# bcm2711_lpa register map
Vendor: BROADCOM; Series: BCM2711; File version: A
CPU: CA72 r0p0, little endian, 2 interrupt priority bits
Registers are 32-bit, read-write, reset 0x0 unless marked. A register's access mark holds for its fields unless they carry their own. Offsets are from the block's base; [hi:lo] are bit positions; {n}, {i} and the like mark numbered series.

## GPIO — Pin level and mux control
Base 0xFE200000
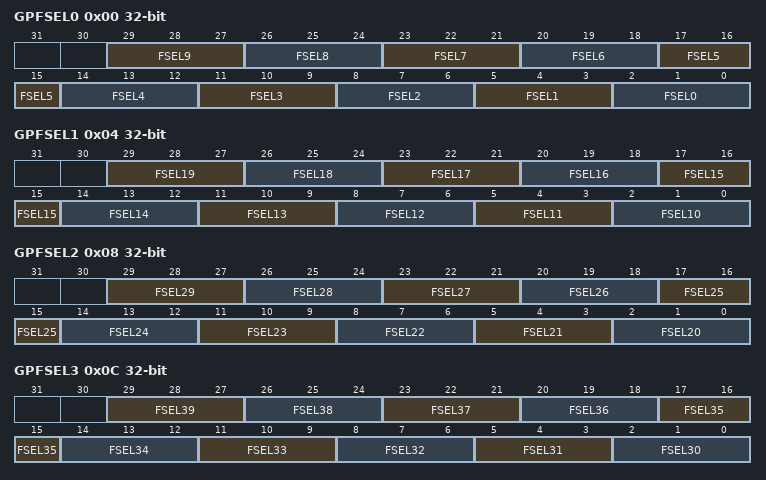
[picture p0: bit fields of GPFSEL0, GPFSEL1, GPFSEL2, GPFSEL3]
0x00 GPFSEL0 reset not defined — GPIO Function Select 0
  [29:27] FSEL9 — Function Select 9
    0=INPUT (Pin is an input); 1=OUTPUT (Pin is an output); 4=SPI0_MISO (Pin is connected to SPI0_MISO); 5=SD1 (Pin is connected to SD1); 6=DPI_D5 (Pin is connected to DPI_D5); 7=BSCSL_MISO (Pin is connected to BSCSL_MISO); 3=RXD4 (Pin is connected to RXD4); 2=SCL4 (Pin is connected to SCL4)
  [26:24] FSEL8 — Function Select 8
    0=INPUT (Pin is an input); 1=OUTPUT (Pin is an output); 4=SPI0_CE0_N (Pin is connected to SPI0_CE0_N); 5=SD0 (Pin is connected to SD0); 6=DPI_D4 (Pin is connected to DPI_D4); 7=BSCSL_CE_N (Pin is connected to BSCSL_CE_N); 3=TXD4 (Pin is connected to TXD4); 2=SDA4 (Pin is connected to SDA4)
  [23:21] FSEL7 — Function Select 7
    0=INPUT (Pin is an input); 1=OUTPUT (Pin is an output); 4=SPI0_CE1_N (Pin is connected to SPI0_CE1_N); 5=SWE_N (Pin is connected to SWE_N); 6=DPI_D3 (Pin is connected to DPI_D3); 7=SPI4_SCLK (Pin is connected to SPI4_SCLK); 3=RTS3 (Pin is connected to RTS3); 2=SCL4 (Pin is connected to SCL4)
  [20:18] FSEL6 — Function Select 6
    0=INPUT (Pin is an input); 1=OUTPUT (Pin is an output); 4=GPCLK2 (Pin is connected to GPCLK2); 5=SOE_N (Pin is connected to SOE_N); 6=DPI_D2 (Pin is connected to DPI_D2); 7=SPI4_MOSI (Pin is connected to SPI4_MOSI); 3=CTS3 (Pin is connected to CTS3); 2=SDA4 (Pin is connected to SDA4)
  [17:15] FSEL5 — Function Select 5
    0=INPUT (Pin is an input); 1=OUTPUT (Pin is an output); 4=GPCLK1 (Pin is connected to GPCLK1); 5=SA0 (Pin is connected to SA0); 6=DPI_D1 (Pin is connected to DPI_D1); 7=SPI4_MISO (Pin is connected to SPI4_MISO); 3=RXD3 (Pin is connected to RXD3); 2=SCL3 (Pin is connected to SCL3)
  [14:12] FSEL4 — Function Select 4
    0=INPUT (Pin is an input); 1=OUTPUT (Pin is an output); 4=GPCLK0 (Pin is connected to GPCLK0); 5=SA1 (Pin is connected to SA1); 6=DPI_D0 (Pin is connected to DPI_D0); 7=SPI4_CE0_N (Pin is connected to SPI4_CE0_N); 3=TXD3 (Pin is connected to TXD3); 2=SDA3 (Pin is connected to SDA3)
  [11:9] FSEL3 — Function Select 3
    0=INPUT (Pin is an input); 1=OUTPUT (Pin is an output); 4=SCL1 (Pin is connected to SCL1); 5=SA2 (Pin is connected to SA2); 6=LCD_HSYNC (Pin is connected to LCD_HSYNC); 7=SPI3_SCLK (Pin is connected to SPI3_SCLK); 3=RTS2 (Pin is connected to RTS2); 2=SCL3 (Pin is connected to SCL3)
  [8:6] FSEL2 — Function Select 2
    0=INPUT (Pin is an input); 1=OUTPUT (Pin is an output); 4=SDA1 (Pin is connected to SDA1); 5=SA3 (Pin is connected to SA3); 6=LCD_VSYNC (Pin is connected to LCD_VSYNC); 7=SPI3_MOSI (Pin is connected to SPI3_MOSI); 3=CTS2 (Pin is connected to CTS2); 2=SDA3 (Pin is connected to SDA3)
  [5:3] FSEL1 — Function Select 1
    0=INPUT (Pin is an input); 1=OUTPUT (Pin is an output); 4=SCL0 (Pin is connected to SCL0); 5=SA4 (Pin is connected to SA4); 6=DE (Pin is connected to DE); 7=SPI3_MISO (Pin is connected to SPI3_MISO); 3=RXD2 (Pin is connected to RXD2); 2=SCL6 (Pin is connected to SCL6)
  [2:0] FSEL0 — Function Select 0
    0=INPUT (Pin is an input); 1=OUTPUT (Pin is an output); 4=SDA0 (Pin is connected to SDA0); 5=SA5 (Pin is connected to SA5); 6=PCLK (Pin is connected to PCLK); 7=SPI3_CE0_N (Pin is connected to SPI3_CE0_N); 3=TXD2 (Pin is connected to TXD2); 2=SDA6 (Pin is connected to SDA6)
0x04 GPFSEL1 reset not defined — GPIO Function Select 1
  [29:27] FSEL19 — Function Select 19
    0=INPUT (Pin is an input); 1=OUTPUT (Pin is an output); 4=PCM_FS (Pin is connected to PCM_FS); 5=SD11 (Pin is connected to SD11); 6=DPI_D15 (Pin is connected to DPI_D15); 7=SPI6_MISO (Pin is connected to SPI6_MISO); 3=SPI1_MISO (Pin is connected to SPI1_MISO); 2=PWM0_1 (Pin is connected to PWM0_1)
  [26:24] FSEL18 — Function Select 18
    0=INPUT (Pin is an input); 1=OUTPUT (Pin is an output); 4=PCM_CLK (Pin is connected to PCM_CLK); 5=SD10 (Pin is connected to SD10); 6=DPI_D14 (Pin is connected to DPI_D14); 7=SPI6_CE0_N (Pin is connected to SPI6_CE0_N); 3=SPI1_CE0_N (Pin is connected to SPI1_CE0_N); 2=PWM0_0 (Pin is connected to PWM0_0)
  [23:21] FSEL17 — Function Select 17
    0=INPUT (Pin is an input); 1=OUTPUT (Pin is an output); 5=SD9 (Pin is connected to SD9); 6=DPI_D13 (Pin is connected to DPI_D13); 7=RTS0 (Pin is connected to RTS0); 3=SPI1_CE1_N (Pin is connected to SPI1_CE1_N); 2=RTS1 (Pin is connected to RTS1)
  [20:18] FSEL16 — Function Select 16
    0=INPUT (Pin is an input); 1=OUTPUT (Pin is an output); 5=SD8 (Pin is connected to SD8); 6=DPI_D12 (Pin is connected to DPI_D12); 7=CTS0 (Pin is connected to CTS0); 3=SPI1_CE2_N (Pin is connected to SPI1_CE2_N); 2=CTS1 (Pin is connected to CTS1)
  [17:15] FSEL15 — Function Select 15
    0=INPUT (Pin is an input); 1=OUTPUT (Pin is an output); 4=RXD0 (Pin is connected to RXD0); 5=SD7 (Pin is connected to SD7); 6=DPI_D11 (Pin is connected to DPI_D11); 7=SPI5_SCLK (Pin is connected to SPI5_SCLK); 3=RTS5 (Pin is connected to RTS5); 2=RXD1 (Pin is connected to RXD1)
  [14:12] FSEL14 — Function Select 14
    0=INPUT (Pin is an input); 1=OUTPUT (Pin is an output); 4=TXD0 (Pin is connected to TXD0); 5=SD6 (Pin is connected to SD6); 6=DPI_D10 (Pin is connected to DPI_D10); 7=SPI5_MOSI (Pin is connected to SPI5_MOSI); 3=CTS5 (Pin is connected to CTS5); 2=TXD1 (Pin is connected to TXD1)
  [11:9] FSEL13 — Function Select 13
    0=INPUT (Pin is an input); 1=OUTPUT (Pin is an output); 4=PWM0_1 (Pin is connected to PWM0_1); 5=SD5 (Pin is connected to SD5); 6=DPI_D9 (Pin is connected to DPI_D9); 7=SPI5_MISO (Pin is connected to SPI5_MISO); 3=RXD5 (Pin is connected to RXD5); 2=SCL5 (Pin is connected to SCL5)
  [8:6] FSEL12 — Function Select 12
    0=INPUT (Pin is an input); 1=OUTPUT (Pin is an output); 4=PWM0_0 (Pin is connected to PWM0_0); 5=SD4 (Pin is connected to SD4); 6=DPI_D8 (Pin is connected to DPI_D8); 7=SPI5_CE0_N (Pin is connected to SPI5_CE0_N); 3=TXD5 (Pin is connected to TXD5); 2=SDA5 (Pin is connected to SDA5)
  [5:3] FSEL11 — Function Select 11
    0=INPUT (Pin is an input); 1=OUTPUT (Pin is an output); 4=SPI0_SCLK (Pin is connected to SPI0_SCLK); 5=SD3 (Pin is connected to SD3); 6=DPI_D7 (Pin is connected to DPI_D7); 7=BSCSL_SCLK (Pin is connected to BSCSL_SCLK); 3=RTS4 (Pin is connected to RTS4); 2=SCL5 (Pin is connected to SCL5)
  [2:0] FSEL10 — Function Select 10
    0=INPUT (Pin is an input); 1=OUTPUT (Pin is an output); 4=SPI0_MOSI (Pin is connected to SPI0_MOSI); 5=SD2 (Pin is connected to SD2); 6=DPI_D6 (Pin is connected to DPI_D6); 7=BSCSL_MOSI (Pin is connected to BSCSL_MOSI); 3=CTS4 (Pin is connected to CTS4); 2=SDA5 (Pin is connected to SDA5)
0x08 GPFSEL2 reset not defined — GPIO Function Select 2
  [29:27] FSEL29 — Function Select 29
    0=INPUT (Pin is an input); 1=OUTPUT (Pin is an output); 4=SCL0 (Pin is connected to SCL0); 5=SA4 (Pin is connected to SA4); 6=PCM_FS (Pin is connected to PCM_FS); 3=MII_A_TX_ERR (Pin is connected to MII_A_TX_ERR); 2=RGMII_MDC (Pin is connected to RGMII_MDC)
  [26:24] FSEL28 — Function Select 28
    0=INPUT (Pin is an input); 1=OUTPUT (Pin is an output); 4=SDA0 (Pin is connected to SDA0); 5=SA5 (Pin is connected to SA5); 6=PCM_CLK (Pin is connected to PCM_CLK); 3=MII_A_RX_ERR (Pin is connected to MII_A_RX_ERR); 2=RGMII_MDIO (Pin is connected to RGMII_MDIO)
  [23:21] FSEL27 — Function Select 27
    0=INPUT (Pin is an input); 1=OUTPUT (Pin is an output); 4=SD0_DAT3 (Pin is connected to SD0_DAT3); 6=DPI_D23 (Pin is connected to DPI_D23); 7=SD1_DAT3 (Pin is connected to SD1_DAT3); 3=ARM_TMS (Pin is connected to ARM_TMS); 2=SPI6_CE1_N (Pin is connected to SPI6_CE1_N)
  [20:18] FSEL26 — Function Select 26
    0=INPUT (Pin is an input); 1=OUTPUT (Pin is an output); 4=SD0_DAT2 (Pin is connected to SD0_DAT2); 6=DPI_D22 (Pin is connected to DPI_D22); 7=SD1_DAT2 (Pin is connected to SD1_DAT2); 3=ARM_TDI (Pin is connected to ARM_TDI); 2=SPI5_CE1_N (Pin is connected to SPI5_CE1_N)
  [17:15] FSEL25 — Function Select 25
    0=INPUT (Pin is an input); 1=OUTPUT (Pin is an output); 4=SD0_DAT1 (Pin is connected to SD0_DAT1); 5=SD17 (Pin is connected to SD17); 6=DPI_D21 (Pin is connected to DPI_D21); 7=SD1_DAT1 (Pin is connected to SD1_DAT1); 3=ARM_TCK (Pin is connected to ARM_TCK); 2=SPI4_CE1_N (Pin is connected to SPI4_CE1_N)
  [14:12] FSEL24 — Function Select 24
    0=INPUT (Pin is an input); 1=OUTPUT (Pin is an output); 4=SD0_DAT0 (Pin is connected to SD0_DAT0); 5=SD16 (Pin is connected to SD16); 6=DPI_D20 (Pin is connected to DPI_D20); 7=SD1_DAT0 (Pin is connected to SD1_DAT0); 3=ARM_TDO (Pin is connected to ARM_TDO); 2=SPI3_CE1_N (Pin is connected to SPI3_CE1_N)
  [11:9] FSEL23 — Function Select 23
    0=INPUT (Pin is an input); 1=OUTPUT (Pin is an output); 4=SD0_CMD (Pin is connected to SD0_CMD); 5=SD15 (Pin is connected to SD15); 6=DPI_D19 (Pin is connected to DPI_D19); 7=SD1_CMD (Pin is connected to SD1_CMD); 3=ARM_RTCK (Pin is connected to ARM_RTCK); 2=SCL6 (Pin is connected to SCL6)
  [8:6] FSEL22 — Function Select 22
    0=INPUT (Pin is an input); 1=OUTPUT (Pin is an output); 4=SD0_CLK (Pin is connected to SD0_CLK); 5=SD14 (Pin is connected to SD14); 6=DPI_D18 (Pin is connected to DPI_D18); 7=SD1_CLK (Pin is connected to SD1_CLK); 3=ARM_TRST (Pin is connected to ARM_TRST); 2=SDA6 (Pin is connected to SDA6)
  [5:3] FSEL21 — Function Select 21
    0=INPUT (Pin is an input); 1=OUTPUT (Pin is an output); 4=PCM_DOUT (Pin is connected to PCM_DOUT); 5=SD13 (Pin is connected to SD13); 6=DPI_D17 (Pin is connected to DPI_D17); 7=SPI6_SCLK (Pin is connected to SPI6_SCLK); 3=SPI1_SCLK (Pin is connected to SPI1_SCLK); 2=GPCLK1 (Pin is connected to GPCLK1)
  [2:0] FSEL20 — Function Select 20
    0=INPUT (Pin is an input); 1=OUTPUT (Pin is an output); 4=PCM_DIN (Pin is connected to PCM_DIN); 5=SD12 (Pin is connected to SD12); 6=DPI_D16 (Pin is connected to DPI_D16); 7=SPI6_MOSI (Pin is connected to SPI6_MOSI); 3=SPI1_MOSI (Pin is connected to SPI1_MOSI); 2=GPCLK0 (Pin is connected to GPCLK0)
0x0C GPFSEL3 reset not defined — GPIO Function Select 3
  [29:27] FSEL39 — Function Select 39
    0=INPUT (Pin is an input); 1=OUTPUT (Pin is an output); 4=SPI0_SCLK (Pin is connected to SPI0_SCLK); 5=SD3 (Pin is connected to SD3); 6=RTS0 (Pin is connected to RTS0); 7=SD1_DAT3 (Pin is connected to SD1_DAT3); 3=RGMII_IRQ (Pin is connected to RGMII_IRQ); 2=MII_A_COL (Pin is connected to MII_A_COL)
  [26:24] FSEL38 — Function Select 38
    0=INPUT (Pin is an input); 1=OUTPUT (Pin is an output); 4=SPI0_MOSI (Pin is connected to SPI0_MOSI); 5=SD2 (Pin is connected to SD2); 6=CTS0 (Pin is connected to CTS0); 7=SD1_DAT2 (Pin is connected to SD1_DAT2); 3=RGMII_MDC (Pin is connected to RGMII_MDC); 2=MII_A_CRS (Pin is connected to MII_A_CRS)
  [23:21] FSEL37 — Function Select 37
    0=INPUT (Pin is an input); 1=OUTPUT (Pin is an output); 4=SPI0_MISO (Pin is connected to SPI0_MISO); 5=SD1 (Pin is connected to SD1); 6=RXD0 (Pin is connected to RXD0); 7=SD1_DAT1 (Pin is connected to SD1_DAT1); 3=RGMII_MDIO (Pin is connected to RGMII_MDIO); 2=MII_A_TX_ERR (Pin is connected to MII_A_TX_ERR)
  [20:18] FSEL36 — Function Select 36
    0=INPUT (Pin is an input); 1=OUTPUT (Pin is an output); 4=SPI0_CE0_N (Pin is connected to SPI0_CE0_N); 5=SD0 (Pin is connected to SD0); 6=TXD0 (Pin is connected to TXD0); 7=SD1_DAT0 (Pin is connected to SD1_DAT0); 3=RGMII_RX_OK (Pin is connected to RGMII_RX_OK); 2=MII_A_RX_ERR (Pin is connected to MII_A_RX_ERR)
  [17:15] FSEL35 — Function Select 35
    0=INPUT (Pin is an input); 1=OUTPUT (Pin is an output); 4=SPI0_CE1_N (Pin is connected to SPI0_CE1_N); 5=SWE_N (Pin is connected to SWE_N); 7=SD1_CMD (Pin is connected to SD1_CMD); 3=RGMII_START_STOP (Pin is connected to RGMII_START_STOP)
  [14:12] FSEL34 — Function Select 34
    0=INPUT (Pin is an input); 1=OUTPUT (Pin is an output); 4=GPCLK0 (Pin is connected to GPCLK0); 5=SOE_N (Pin is connected to SOE_N); 7=SD1_CLK (Pin is connected to SD1_CLK); 3=SD_CARD_LED (Pin is connected to SD_CARD_LED); 2=RGMII_IRQ (Pin is connected to RGMII_IRQ)
  [11:9] FSEL33 — Function Select 33
    0=INPUT (Pin is an input); 1=OUTPUT (Pin is an output); 5=SA0 (Pin is connected to SA0); 7=RXD0 (Pin is connected to RXD0); 3=SD_CARD_WRPROT (Pin is connected to SD_CARD_WRPROT); 2=RXD1 (Pin is connected to RXD1)
  [8:6] FSEL32 — Function Select 32
    0=INPUT (Pin is an input); 1=OUTPUT (Pin is an output); 4=GPCLK0 (Pin is connected to GPCLK0); 5=SA1 (Pin is connected to SA1); 7=TXD0 (Pin is connected to TXD0); 3=SD_CARD_PRES (Pin is connected to SD_CARD_PRES); 2=TXD1 (Pin is connected to TXD1)
  [5:3] FSEL31 — Function Select 31
    0=INPUT (Pin is an input); 1=OUTPUT (Pin is an output); 5=SA2 (Pin is connected to SA2); 6=PCM_DOUT (Pin is connected to PCM_DOUT); 7=RTS0 (Pin is connected to RTS0); 3=MII_A_COL (Pin is connected to MII_A_COL); 2=RTS1 (Pin is connected to RTS1)
  [2:0] FSEL30 — Function Select 30
    0=INPUT (Pin is an input); 1=OUTPUT (Pin is an output); 5=SA3 (Pin is connected to SA3); 6=PCM_DIN (Pin is connected to PCM_DIN); 7=CTS0 (Pin is connected to CTS0); 3=MII_A_CRS (Pin is connected to MII_A_CRS); 2=CTS1 (Pin is connected to CTS1)
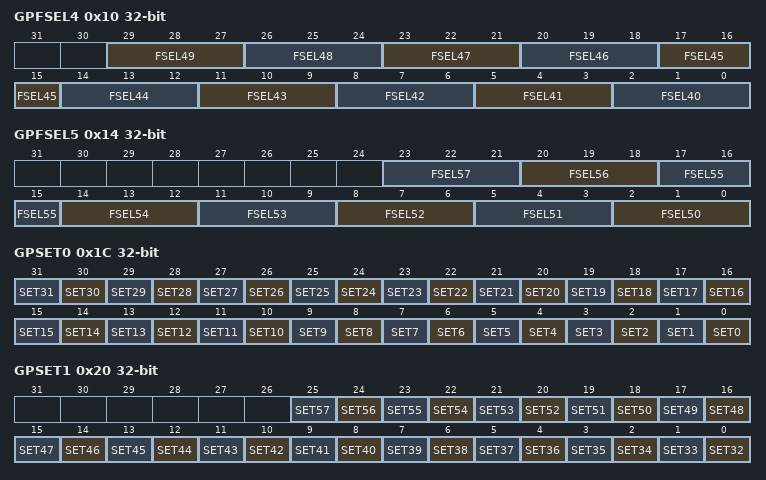
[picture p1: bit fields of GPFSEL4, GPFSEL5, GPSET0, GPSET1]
0x10 GPFSEL4 reset not defined — GPIO Function Select 4
  [29:27] FSEL49 — Function Select 49
    0=INPUT (Pin is an input); 1=OUTPUT (Pin is an output); 7=SD1_CMD (Pin is connected to SD1_CMD)
  [26:24] FSEL48 — Function Select 48
    0=INPUT (Pin is an input); 1=OUTPUT (Pin is an output); 7=SD1_CLK (Pin is connected to SD1_CLK)
  [23:21] FSEL47 — Function Select 47
    0=INPUT (Pin is an input); 1=OUTPUT (Pin is an output)
  [20:18] FSEL46 — Function Select 46
    0=INPUT (Pin is an input); 1=OUTPUT (Pin is an output)
  [17:15] FSEL45 — Function Select 45
    0=INPUT (Pin is an input); 1=OUTPUT (Pin is an output); 4=PWM0_1 (Pin is connected to PWM0_1); 5=SCL0 (Pin is connected to SCL0); 6=SCL1 (Pin is connected to SCL1); 2=SD_CARD_PWR0 (Pin is connected to SD_CARD_PWR0)
  [14:12] FSEL44 — Function Select 44
    0=INPUT (Pin is an input); 1=OUTPUT (Pin is an output); 4=GPCLK1 (Pin is connected to GPCLK1); 5=SDA0 (Pin is connected to SDA0); 6=SDA1 (Pin is connected to SDA1); 2=SD_CARD_VOLT (Pin is connected to SD_CARD_VOLT)
  [11:9] FSEL43 — Function Select 43
    0=INPUT (Pin is an input); 1=OUTPUT (Pin is an output); 4=GPCLK2 (Pin is connected to GPCLK2); 5=SD7 (Pin is connected to SD7); 7=SD1_DAT7 (Pin is connected to SD1_DAT7); 2=RTS1 (Pin is connected to RTS1)
  [8:6] FSEL42 — Function Select 42
    0=INPUT (Pin is an input); 1=OUTPUT (Pin is an output); 4=GPCLK1 (Pin is connected to GPCLK1); 5=SD6 (Pin is connected to SD6); 7=SD1_DAT6 (Pin is connected to SD1_DAT6); 2=CTS1 (Pin is connected to CTS1)
  [5:3] FSEL41 — Function Select 41
    0=INPUT (Pin is an input); 1=OUTPUT (Pin is an output); 4=PWM1_1 (Pin is connected to PWM1_1); 5=SD5 (Pin is connected to SD5); 7=SD1_DAT5 (Pin is connected to SD1_DAT5); 2=RXD1 (Pin is connected to RXD1)
  [2:0] FSEL40 — Function Select 40
    0=INPUT (Pin is an input); 1=OUTPUT (Pin is an output); 4=PWM1_0 (Pin is connected to PWM1_0); 5=SD4 (Pin is connected to SD4); 7=SD1_DAT4 (Pin is connected to SD1_DAT4); 2=TXD1 (Pin is connected to TXD1)
0x14 GPFSEL5 reset not defined — GPIO Function Select 5
  [3n-148:3n-150] FSEL{n} (n=54..57) — Function Select {n}
    0=INPUT (Pin is an input); 1=OUTPUT (Pin is an output)
  [3n-148:3n-150] FSEL{n} (n=50..53) — Function Select {n}
    0=INPUT (Pin is an input); 1=OUTPUT (Pin is an output); 7=SD1_DAT{n-50} (Pin is connected to SD1_DAT{n-50})
0x1C GPSET0 wo reset not defined write-1-sets — GPIO Pin Output Set 0
  [n] SET{n} (n=0..31)
0x20 GPSET1 wo reset not defined write-1-sets — GPIO Pin Output Set 1
  [n-32] SET{n} (n=32..57)
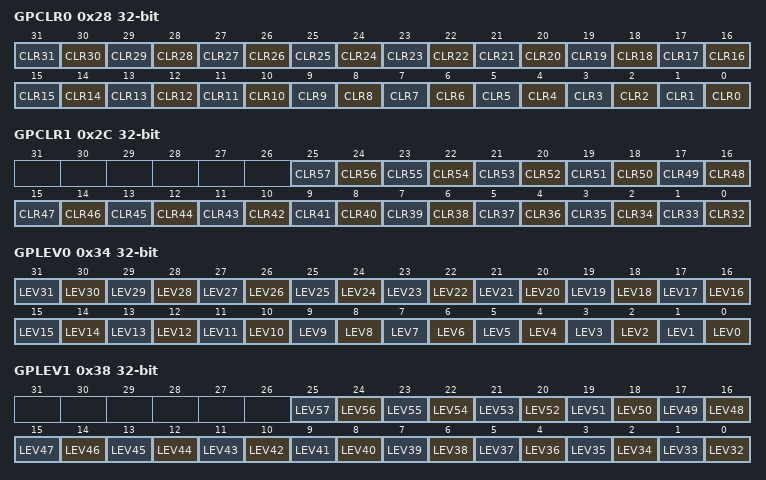
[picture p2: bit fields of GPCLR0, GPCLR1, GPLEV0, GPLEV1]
0x28 GPCLR0 wo reset not defined write-1-clears — GPIO Pin Output Clear 0
  [n] CLR{n} (n=0..31) — Clear {n}
0x2C GPCLR1 wo reset not defined write-1-clears — GPIO Pin Output Clear 1
  [n-32] CLR{n} (n=32..57) — Clear {n}
0x34 GPLEV0 ro reset not defined — GPIO Pin Level 0
  [n] LEV{n} (n=0..31) — Level {n}
0x38 GPLEV1 ro reset not defined — GPIO Pin Level 1
  [n-32] LEV{n} (n=32..57) — Level {n}
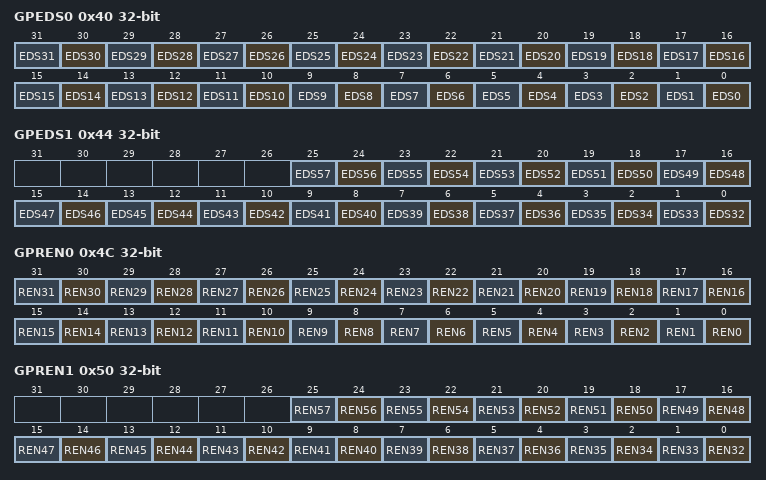
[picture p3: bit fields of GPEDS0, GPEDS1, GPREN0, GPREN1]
0x40 GPEDS0 reset not defined write-1-clears — GPIO Pin Event Detect Status 0
  [n] EDS{n} (n=0..31) — Event detected {n}
0x44 GPEDS1 reset not defined write-1-clears — GPIO Pin Event Detect Status 1
  [n-32] EDS{n} (n=32..57) — Event detected {n}
0x4C GPREN0 reset not defined — GPIO Pin Rising Edge Detect Enable 0
  [n] REN{n} (n=0..31) — Rising edge enabled {n}
0x50 GPREN1 reset not defined — GPIO Pin Rising Edge Detect Enable 1
  [n-32] REN{n} (n=32..57) — Rising edge enabled {n}
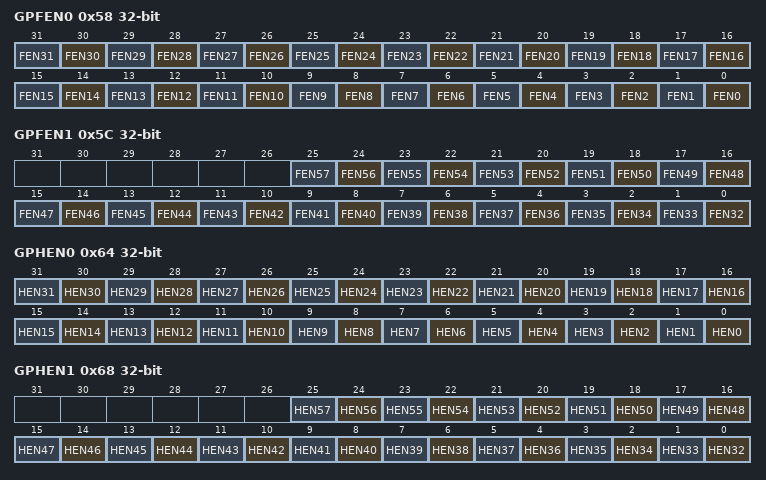
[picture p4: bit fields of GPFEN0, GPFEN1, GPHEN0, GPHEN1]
0x58 GPFEN0 reset not defined — GPIO Pin Falling Edge Detect Enable 0
  [n] FEN{n} (n=0..31) — Falling edge enabled {n}
0x5C GPFEN1 reset not defined — GPIO Pin Falling Edge Detect Enable 1
  [n-32] FEN{n} (n=32..57) — Falling edge enabled {n}
0x64 GPHEN0 reset not defined — GPIO Pin High Detect Enable 0
  [n] HEN{n} (n=0..31) — High detect enabled {n}
0x68 GPHEN1 reset not defined — GPIO Pin High Detect Enable 1
  [n-32] HEN{n} (n=32..57) — High detect enabled {n}
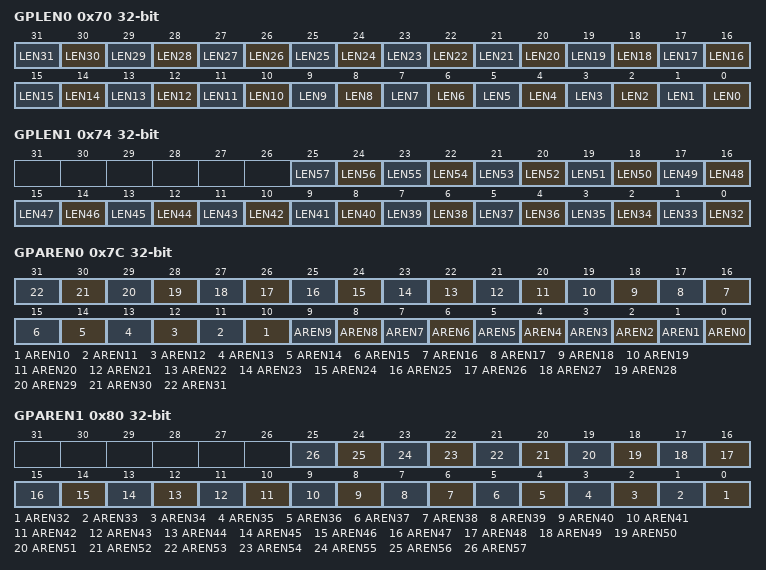
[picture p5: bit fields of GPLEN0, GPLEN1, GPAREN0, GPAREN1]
0x70 GPLEN0 reset not defined — GPIO Pin Low Detect Enable 0
  [n] LEN{n} (n=0..31) — Low detect enabled {n}
0x74 GPLEN1 reset not defined — GPIO Pin Low Detect Enable 1
  [n-32] LEN{n} (n=32..57) — Low detect enabled {n}
0x7C GPAREN0 reset not defined — GPIO Pin Async. Rising Edge Detect 0
  [n] AREN{n} (n=0..31) — Async rising enabled {n}
0x80 GPAREN1 reset not defined — GPIO Pin Async. Rising Edge Detect 1
  [n-32] AREN{n} (n=32..57) — Async rising enabled {n}
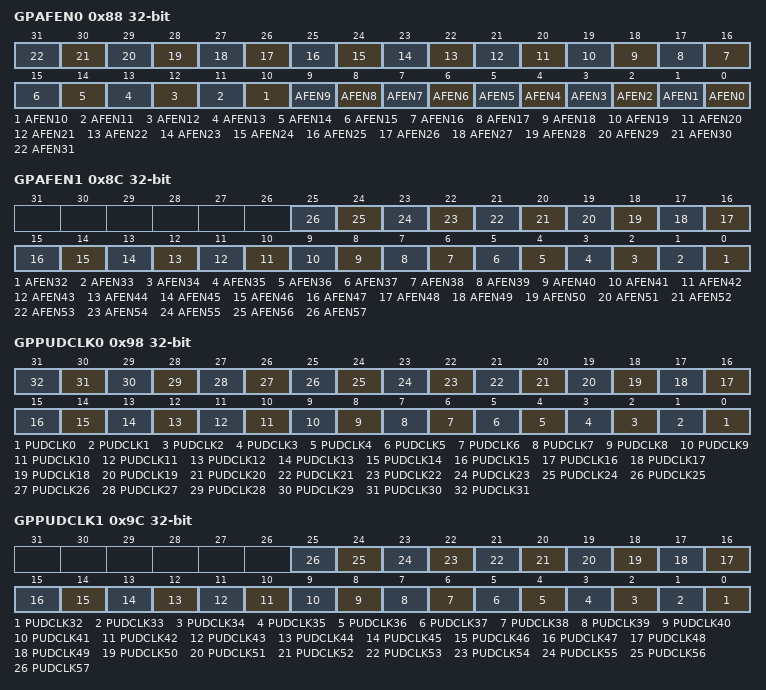
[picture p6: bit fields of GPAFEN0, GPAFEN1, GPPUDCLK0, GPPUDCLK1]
0x88 GPAFEN0 reset not defined — GPIO Pin Async. Falling Edge Detect 0
  [n] AFEN{n} (n=0..31) — Async falling enabled {n}
0x8C GPAFEN1 reset not defined — GPIO Pin Async. Falling Edge Detect 1
  [n-32] AFEN{n} (n=32..57) — Async falling enabled {n}
0x94 GPPUD reset not defined — GPIO Pin Pull-up/down Enable
  [1:0] PUD — GPIO Pin Pull-up/down
    0=NONE (No pull); 1=DOWN (Pull down); 2=UP (Pull up)
0x98 GPPUDCLK0 reset not defined — GPIO Pin Pull-up/down Enable Clock 0
  [n] PUDCLK{n} (n=0..31) — Assert clock on line {n}
0x9C GPPUDCLK1 reset not defined — GPIO Pin Pull-up/down Enable Clock 1
  [n-32] PUDCLK{n} (n=32..57) — Assert clock on line {n}
0xD0 EXTRA_MUX reset not defined — Undocumented multiplexing bits
  [1] SDIO — Switch peripheral connection to undocumented SDIO pins used on Pi 4
    0=SDHOST (Connect the newer SD host); 1=ARASAN (Connect Arasan SD/EMMC host)
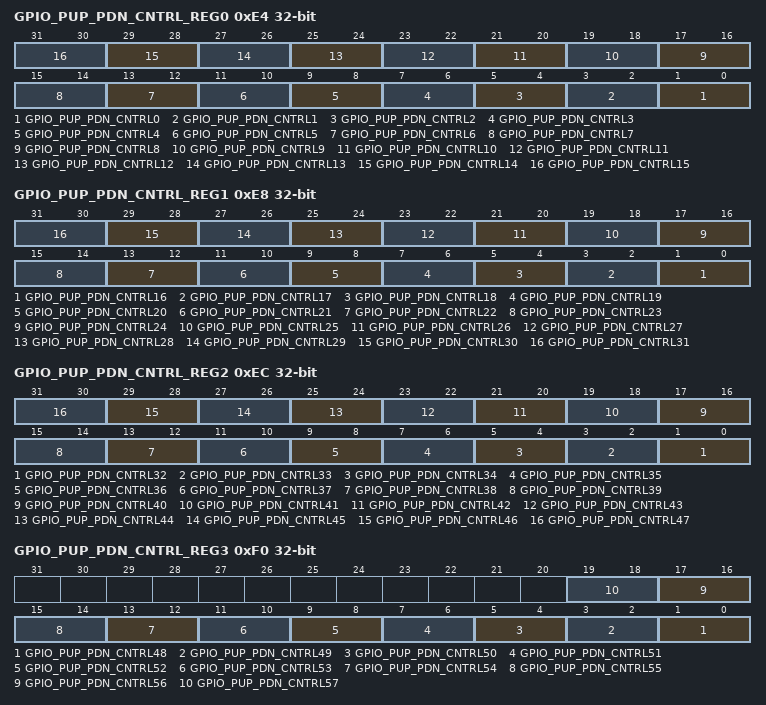
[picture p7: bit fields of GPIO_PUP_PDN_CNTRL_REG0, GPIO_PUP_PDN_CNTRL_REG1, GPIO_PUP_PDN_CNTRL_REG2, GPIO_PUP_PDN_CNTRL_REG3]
0xE4 GPIO_PUP_PDN_CNTRL_REG0 reset not defined — GPIO Pull-up / Pull-down Register 0
  [all] fields
    0=NONE (No pull); 1=UP (Pull up); 2=DOWN (Pull down)
  [2n+1:2n] GPIO_PUP_PDN_CNTRL{n} (n=0..15) — Resistor select for {n}
0xE8 GPIO_PUP_PDN_CNTRL_REG1 access not given reset not defined — GPIO Pull-up / Pull-down Register 1
  [all] fields
    0=NONE (No pull); 1=UP (Pull up); 2=DOWN (Pull down)
  [2n-31:2n-32] GPIO_PUP_PDN_CNTRL{n} (n=16..31) — Resistor select for {n}
0xEC GPIO_PUP_PDN_CNTRL_REG2 access not given reset not defined — GPIO Pull-up / Pull-down Register 2
  [all] fields
    0=NONE (No pull); 1=UP (Pull up); 2=DOWN (Pull down)
  [2n-63:2n-64] GPIO_PUP_PDN_CNTRL{n} (n=32..47) — Resistor select for {n}
0xF0 GPIO_PUP_PDN_CNTRL_REG3 access not given reset not defined — GPIO Pull-up / Pull-down Register 3
  [all] fields
    0=NONE (No pull); 1=UP (Pull up); 2=DOWN (Pull down)
  [2n-95:2n-96] GPIO_PUP_PDN_CNTRL{n} (n=48..57) — Resistor select for {n}
